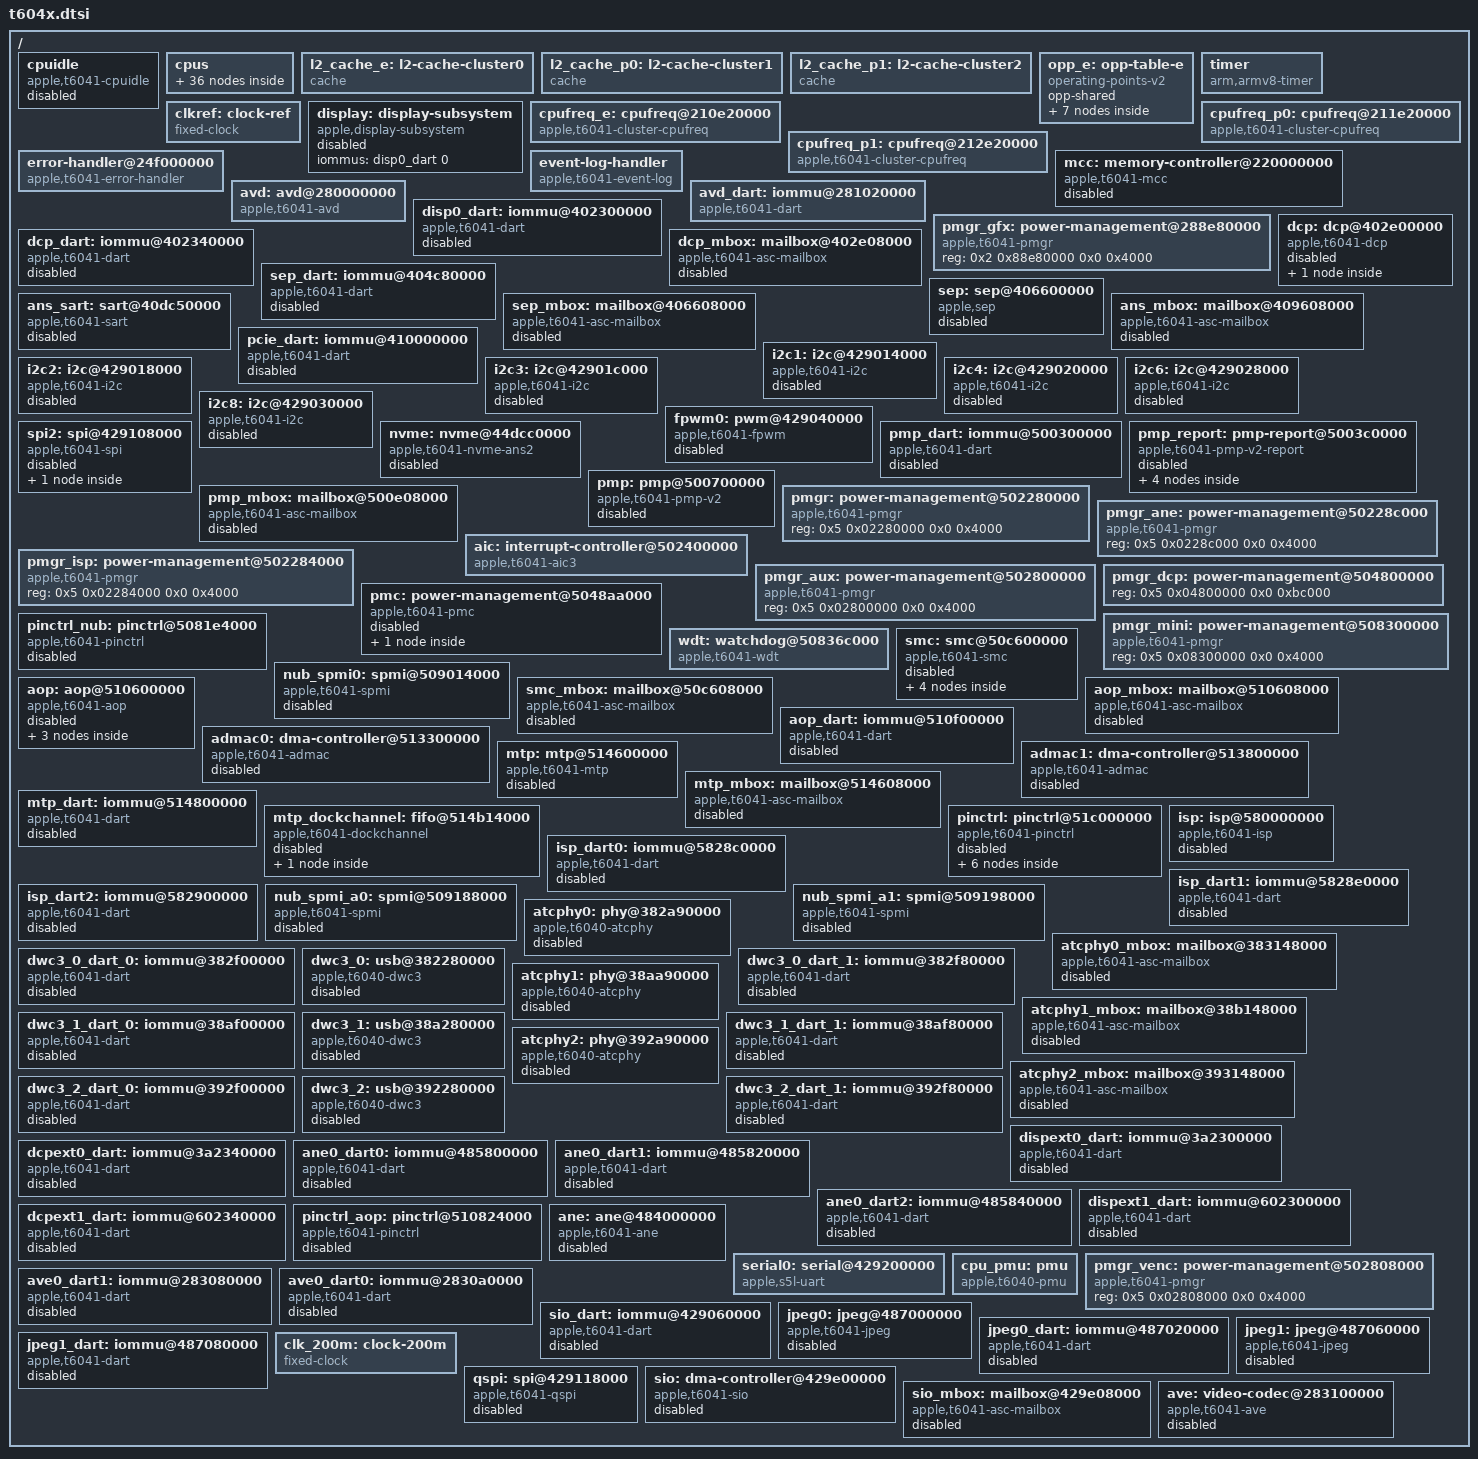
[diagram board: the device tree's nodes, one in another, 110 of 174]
// SPDX-License-Identifier: GPL-2.0+ OR MIT
/*
 * Apple T604x SoC base
 *
 * Unit addresses are the Apple Device Tree's /arm-io addresses plus the
 * 0x2_00000000 arm-io base. The nodes sit at the root, not under a
 * simple-bus: the boot loader edits several of them by path. The blocks
 * known to need non-posted writes carry nonposted-mmio themselves.
 *
 * Copyright The Asahi Linux Contributors
 */

#include <dt-bindings/gpio/gpio.h>
#include <dt-bindings/interrupt-controller/apple-aic.h>
#include <dt-bindings/interrupt-controller/irq.h>
#include <dt-bindings/pinctrl/apple.h>
#include <dt-bindings/phy/phy.h>
#include <dt-bindings/spmi/spmi.h>

/ {
	#address-cells = <2>;
	#size-cells = <2>;

	cpuidle: cpuidle {
		compatible = "apple,t6041-cpuidle";
		status = "disabled";
	};

	cpus {
		#address-cells = <2>;
		#size-cells = <0>;

		/*
		 * The clusters are MPIDR Aff1, which are also the L2 groups.
		 * capacity-dmips-mhz comes from pinned single-core throughput
		 * at the lowest p-state (E 1018 MHz, P 1257 MHz): E/P is 0.652
		 * per MHz, so E 668 and P 1024.
		 */
		cpu-map {
			cluster0 {
				core0 {
					cpu = <&cpu_e0>;
				};
				core1 {
					cpu = <&cpu_e1>;
				};
				core2 {
					cpu = <&cpu_e2>;
				};
				core3 {
					cpu = <&cpu_e3>;
				};
			};

			cluster1 {
				core0 {
					cpu = <&cpu_p00>;
				};
				core1 {
					cpu = <&cpu_p01>;
				};
				core2 {
					cpu = <&cpu_p02>;
				};
				core3 {
					cpu = <&cpu_p03>;
				};
				core4 {
					cpu = <&cpu_p04>;
				};
				core5 {
					cpu = <&cpu_p05>;
				};
			};

			cluster2 {
				core0 {
					cpu = <&cpu_p10>;
				};
				core1 {
					cpu = <&cpu_p11>;
				};
				core2 {
					cpu = <&cpu_p12>;
				};
				core3 {
					cpu = <&cpu_p13>;
				};
				core4 {
					cpu = <&cpu_p14>;
				};
				core5 {
					cpu = <&cpu_p15>;
				};
			};
		};

		/* m1n1 requires CPU nodes in MPIDR order. */
		cpu_e0: cpu@0 {
			compatible = "apple,brava-e";
			device_type = "cpu";
			reg = <0x0 0x0>;
			enable-method = "spin-table";
			cpu-release-addr = <0 0>; /* To be filled by loader */
			next-level-cache = <&l2_cache_e>;
			operating-points-v2 = <&opp_e>;
			capacity-dmips-mhz = <668>;
			performance-domains = <&cpufreq_e>;
			#cooling-cells = <2>;
		};

		cpu_e1: cpu@1 {
			compatible = "apple,brava-e";
			device_type = "cpu";
			reg = <0x0 0x1>;
			enable-method = "spin-table";
			cpu-release-addr = <0 0>; /* To be filled by loader */
			next-level-cache = <&l2_cache_e>;
			operating-points-v2 = <&opp_e>;
			capacity-dmips-mhz = <668>;
			performance-domains = <&cpufreq_e>;
			#cooling-cells = <2>;
		};

		cpu_e2: cpu@2 {
			compatible = "apple,brava-e";
			device_type = "cpu";
			reg = <0x0 0x2>;
			enable-method = "spin-table";
			cpu-release-addr = <0 0>; /* To be filled by loader */
			next-level-cache = <&l2_cache_e>;
			operating-points-v2 = <&opp_e>;
			capacity-dmips-mhz = <668>;
			performance-domains = <&cpufreq_e>;
			#cooling-cells = <2>;
		};

		cpu_e3: cpu@3 {
			compatible = "apple,brava-e";
			device_type = "cpu";
			reg = <0x0 0x3>;
			enable-method = "spin-table";
			cpu-release-addr = <0 0>; /* To be filled by loader */
			next-level-cache = <&l2_cache_e>;
			operating-points-v2 = <&opp_e>;
			capacity-dmips-mhz = <668>;
			performance-domains = <&cpufreq_e>;
			#cooling-cells = <2>;
		};

		/* The boot CPU: the boot loader enters the kernel on it. */
		cpu_p00: cpu@10100 {
			compatible = "apple,brava-p";
			device_type = "cpu";
			reg = <0x0 0x10100>;
			next-level-cache = <&l2_cache_p0>;
			operating-points-v2 = <&opp_p0>;
			capacity-dmips-mhz = <1024>;
			performance-domains = <&cpufreq_p0>;
			#cooling-cells = <2>;
		};

		cpu_p01: cpu@10101 {
			compatible = "apple,brava-p";
			device_type = "cpu";
			reg = <0x0 0x10101>;
			enable-method = "spin-table";
			cpu-release-addr = <0 0>; /* To be filled by loader */
			next-level-cache = <&l2_cache_p0>;
			operating-points-v2 = <&opp_p0>;
			capacity-dmips-mhz = <1024>;
			performance-domains = <&cpufreq_p0>;
			#cooling-cells = <2>;
		};

		cpu_p02: cpu@10102 {
			compatible = "apple,brava-p";
			device_type = "cpu";
			reg = <0x0 0x10102>;
			enable-method = "spin-table";
			cpu-release-addr = <0 0>; /* To be filled by loader */
			next-level-cache = <&l2_cache_p0>;
			operating-points-v2 = <&opp_p0>;
			capacity-dmips-mhz = <1024>;
			performance-domains = <&cpufreq_p0>;
			#cooling-cells = <2>;
		};

		cpu_p03: cpu@10103 {
			compatible = "apple,brava-p";
			device_type = "cpu";
			reg = <0x0 0x10103>;
			enable-method = "spin-table";
			cpu-release-addr = <0 0>; /* To be filled by loader */
			next-level-cache = <&l2_cache_p0>;
			operating-points-v2 = <&opp_p0>;
			capacity-dmips-mhz = <1024>;
			performance-domains = <&cpufreq_p0>;
			#cooling-cells = <2>;
		};

		cpu_p04: cpu@10104 {
			compatible = "apple,brava-p";
			device_type = "cpu";
			reg = <0x0 0x10104>;
			enable-method = "spin-table";
			cpu-release-addr = <0 0>; /* To be filled by loader */
			next-level-cache = <&l2_cache_p0>;
			operating-points-v2 = <&opp_p0>;
			capacity-dmips-mhz = <1024>;
			performance-domains = <&cpufreq_p0>;
			#cooling-cells = <2>;
		};

		cpu_p05: cpu@10105 {
			compatible = "apple,brava-p";
			device_type = "cpu";
			reg = <0x0 0x10105>;
			enable-method = "spin-table";
			cpu-release-addr = <0 0>;
			next-level-cache = <&l2_cache_p0>;
			operating-points-v2 = <&opp_p0>;
			capacity-dmips-mhz = <1024>;
			performance-domains = <&cpufreq_p0>;
			#cooling-cells = <2>;
		};

		cpu_p10: cpu@10200 {
			compatible = "apple,brava-p";
			device_type = "cpu";
			reg = <0x0 0x10200>;
			enable-method = "spin-table";
			cpu-release-addr = <0 0>; /* To be filled by loader */
			next-level-cache = <&l2_cache_p1>;
			operating-points-v2 = <&opp_p1>;
			capacity-dmips-mhz = <1024>;
			performance-domains = <&cpufreq_p1>;
			#cooling-cells = <2>;
		};

		cpu_p11: cpu@10201 {
			compatible = "apple,brava-p";
			device_type = "cpu";
			reg = <0x0 0x10201>;
			enable-method = "spin-table";
			cpu-release-addr = <0 0>; /* To be filled by loader */
			next-level-cache = <&l2_cache_p1>;
			operating-points-v2 = <&opp_p1>;
			capacity-dmips-mhz = <1024>;
			performance-domains = <&cpufreq_p1>;
			#cooling-cells = <2>;
		};

		cpu_p12: cpu@10202 {
			compatible = "apple,brava-p";
			device_type = "cpu";
			reg = <0x0 0x10202>;
			enable-method = "spin-table";
			cpu-release-addr = <0 0>; /* To be filled by loader */
			next-level-cache = <&l2_cache_p1>;
			operating-points-v2 = <&opp_p1>;
			capacity-dmips-mhz = <1024>;
			performance-domains = <&cpufreq_p1>;
			#cooling-cells = <2>;
		};

		cpu_p13: cpu@10203 {
			compatible = "apple,brava-p";
			device_type = "cpu";
			reg = <0x0 0x10203>;
			enable-method = "spin-table";
			cpu-release-addr = <0 0>; /* To be filled by loader */
			next-level-cache = <&l2_cache_p1>;
			operating-points-v2 = <&opp_p1>;
			capacity-dmips-mhz = <1024>;
			performance-domains = <&cpufreq_p1>;
			#cooling-cells = <2>;
		};

		cpu_p14: cpu@10204 {
			compatible = "apple,brava-p";
			device_type = "cpu";
			reg = <0x0 0x10204>;
			enable-method = "spin-table";
			cpu-release-addr = <0 0>; /* To be filled by loader */
			next-level-cache = <&l2_cache_p1>;
			operating-points-v2 = <&opp_p1>;
			capacity-dmips-mhz = <1024>;
			performance-domains = <&cpufreq_p1>;
			#cooling-cells = <2>;
		};

		cpu_p15: cpu@10205 {
			compatible = "apple,brava-p";
			device_type = "cpu";
			reg = <0x0 0x10205>;
			enable-method = "spin-table";
			cpu-release-addr = <0 0>;
			next-level-cache = <&l2_cache_p1>;
			operating-points-v2 = <&opp_p1>;
			capacity-dmips-mhz = <1024>;
			performance-domains = <&cpufreq_p1>;
			#cooling-cells = <2>;
		};
	};

	l2_cache_e: l2-cache-cluster0 {
		compatible = "cache";
		cache-level = <2>;
		cache-unified;
		cache-size = <0x400000>;
	};

	l2_cache_p0: l2-cache-cluster1 {
		compatible = "cache";
		cache-level = <2>;
		cache-unified;
		cache-size = <0x1000000>;
	};

	l2_cache_p1: l2-cache-cluster2 {
		compatible = "cache";
		cache-level = <2>;
		cache-unified;
		cache-size = <0x1000000>;
	};

	/*
	 * DVFS states from the ADT /arm-io/pmgr voltage-states1-sram (E),
	 * voltage-states5-sram (P0) and voltage-states13-sram (P1), word 0 in
	 * kHz; opp-level is the hardware p-state. Each P cluster has its own
	 * table: opp-shared means one clock domain per table.
	 *
	 * opp-microwatt is one busy core's power on a J616s, from the SMC
	 * core-rail meters (P0 PR0b, P1 PP0b, E PP2b). The P values follow a
	 * k * V^2 * f + c fit, as the PMP clips the two top states within
	 * seconds; the E values are the idle cluster plus a quarter of the
	 * four-core increase, since one E core does not register below
	 * 2352 MHz.
	 */
	opp_e: opp-table-e {
		compatible = "operating-points-v2";
		opp-shared;

		opp01 {
			opp-hz = /bits/ 64 <1020000000>;
			opp-level = <1>;
		};
		opp02 {
			opp-hz = /bits/ 64 <1404000000>;
			opp-level = <2>;
		};
		opp03 {
			opp-hz = /bits/ 64 <1788000000>;
			opp-level = <3>;
		};
		opp04 {
			opp-hz = /bits/ 64 <2112000000>;
			opp-level = <4>;
		};
		opp05 {
			opp-hz = /bits/ 64 <2352000000>;
			opp-level = <5>;
		};
		opp06 {
			opp-hz = /bits/ 64 <2532000000>;
			opp-level = <6>;
		};
		opp07 {
			opp-hz = /bits/ 64 <2592000000>;
			opp-level = <7>;
		};
	};

	timer {
		compatible = "arm,armv8-timer";
		interrupt-parent = <&aic>;
		interrupt-names = "phys", "virt", "hyp-phys", "hyp-virt";
		interrupts = <AIC_FIQ AIC_TMR_GUEST_PHYS IRQ_TYPE_LEVEL_HIGH>,
			     <AIC_FIQ AIC_TMR_GUEST_VIRT IRQ_TYPE_LEVEL_HIGH>,
			     <AIC_FIQ AIC_TMR_HV_PHYS IRQ_TYPE_LEVEL_HIGH>,
			     <AIC_FIQ AIC_TMR_HV_VIRT IRQ_TYPE_LEVEL_HIGH>;
	};

	/* The 24 MHz reference clock (ADT clock-ids 4) of the I2C, PWM and watchdog blocks */
	clkref: clock-ref {
		compatible = "fixed-clock";
		#clock-cells = <0>;
		clock-frequency = <24000000>;
		clock-output-names = "clkref";
	};

	/*
	 * Display component master. It has no registers; the boot loader
	 * enables it with the DCP when it hands the display over.
	 */
	display: display-subsystem {
		compatible = "apple,display-subsystem";
		iommus = <&disp0_dart 0>;
		status = "disabled";
	};

	cpufreq_e: cpufreq@210e20000 {
		compatible = "apple,t6041-cluster-cpufreq", "apple,t8112-cluster-cpufreq";
		reg = <0x2 0x10e20000 0x0 0x1000>;
		nonposted-mmio;
		#performance-domain-cells = <0>;
		/* PMP fast die-temperature effort, byte 0 of FAST-DIE-CE */
		apple,fast-die-effort = <&pmp_report 0>;
	};

	cpufreq_p0: cpufreq@211e20000 {
		compatible = "apple,t6041-cluster-cpufreq", "apple,t8112-cluster-cpufreq";
		reg = <0x2 0x11e20000 0x0 0x1000>;
		nonposted-mmio;
		#performance-domain-cells = <0>;
		apple,fast-die-effort = <&pmp_report 1>;
	};

	cpufreq_p1: cpufreq@212e20000 {
		compatible = "apple,t6041-cluster-cpufreq", "apple,t8112-cluster-cpufreq";
		reg = <0x2 0x12e20000 0x0 0x1000>;
		nonposted-mmio;
		#performance-domain-cells = <0>;
		apple,fast-die-effort = <&pmp_report 2>;
	};

	error-handler@24f000000 {
		compatible = "apple,t6041-error-handler", "apple,soc-error-handler";
		reg = <0x2 0x4f000000 0x0 0x00005000>,
		      <0x2 0x50000000 0x0 0x00005000>,
		      <0x2 0x51000000 0x0 0x00005000>,
		      <0x2 0x63100000 0x0 0x00005000>,
		      <0x2 0x64100000 0x0 0x00005000>,
		      <0x2 0x65100000 0x0 0x00005000>,
		      <0x2 0x66100000 0x0 0x00005000>,
		      <0x2 0x63000000 0x0 0x00005000>,
		      <0x2 0x64000000 0x0 0x00005000>,
		      <0x2 0x65000000 0x0 0x00005000>,
		      <0x2 0x66000000 0x0 0x00005000>,
		      <0x2 0x6d000000 0x0 0x00005000>,
		      <0x2 0x6e000000 0x0 0x00005000>,
		      <0x2 0x6f000000 0x0 0x00005000>,
		      <0x2 0x70000000 0x0 0x00005000>,
		      <0x2 0x71000000 0x0 0x00005000>,
		      <0x2 0x72000000 0x0 0x00005000>,
		      <0x2 0x73000000 0x0 0x00005000>,
		      <0x2 0x74000000 0x0 0x00005000>,
		      <0x2 0x5a000000 0x0 0x00005000>,
		      <0x2 0x5b000000 0x0 0x00005000>,
		      <0x2 0x6b000000 0x0 0x00005000>,
		      <0x2 0x6c000000 0x0 0x00005000>,
		      <0x2 0x7b000000 0x0 0x00005000>,
		      <0x2 0x7c000000 0x0 0x00005000>;
		interrupt-parent = <&aic>;
		interrupts = <AIC_IRQ 675 IRQ_TYPE_LEVEL_HIGH>,
			     <AIC_IRQ 684 IRQ_TYPE_LEVEL_HIGH>,
			     <AIC_IRQ 674 IRQ_TYPE_LEVEL_HIGH>,
			     <AIC_IRQ 681 IRQ_TYPE_LEVEL_HIGH>,
			     <AIC_IRQ 679 IRQ_TYPE_LEVEL_HIGH>,
			     <AIC_IRQ 677 IRQ_TYPE_LEVEL_HIGH>,
			     <AIC_IRQ 678 IRQ_TYPE_LEVEL_HIGH>,
			     <AIC_IRQ 682 IRQ_TYPE_LEVEL_HIGH>,
			     <AIC_IRQ 680 IRQ_TYPE_LEVEL_HIGH>,
			     <AIC_IRQ 411 IRQ_TYPE_LEVEL_HIGH>,
			     <AIC_IRQ 487 IRQ_TYPE_LEVEL_HIGH>,
			     <AIC_IRQ 490 IRQ_TYPE_LEVEL_HIGH>,
			     <AIC_IRQ 493 IRQ_TYPE_LEVEL_HIGH>,
			     <AIC_IRQ 496 IRQ_TYPE_LEVEL_HIGH>,
			     <AIC_IRQ 499 IRQ_TYPE_LEVEL_HIGH>,
			     <AIC_IRQ 502 IRQ_TYPE_LEVEL_HIGH>,
			     <AIC_IRQ 505 IRQ_TYPE_LEVEL_HIGH>,
			     <AIC_IRQ 508 IRQ_TYPE_LEVEL_HIGH>,
			     <AIC_IRQ 511 IRQ_TYPE_LEVEL_HIGH>,
			     <AIC_IRQ 514 IRQ_TYPE_LEVEL_HIGH>,
			     <AIC_IRQ 517 IRQ_TYPE_LEVEL_HIGH>,
			     <AIC_IRQ 520 IRQ_TYPE_LEVEL_HIGH>,
			     <AIC_IRQ 523 IRQ_TYPE_LEVEL_HIGH>,
			     <AIC_IRQ 526 IRQ_TYPE_LEVEL_HIGH>,
			     <AIC_IRQ 529 IRQ_TYPE_LEVEL_HIGH>,
			     <AIC_IRQ 532 IRQ_TYPE_LEVEL_HIGH>,
			     <AIC_IRQ 1000 IRQ_TYPE_LEVEL_HIGH>,
			     <AIC_IRQ 386 IRQ_TYPE_LEVEL_HIGH>,
			     <AIC_IRQ 882 IRQ_TYPE_LEVEL_HIGH>,
			     <AIC_IRQ 583 IRQ_TYPE_LEVEL_HIGH>,
			     <AIC_IRQ 584 IRQ_TYPE_LEVEL_HIGH>,
			     <AIC_IRQ 585 IRQ_TYPE_LEVEL_HIGH>,
			     <AIC_IRQ 586 IRQ_TYPE_LEVEL_HIGH>,
			     <AIC_IRQ 589 IRQ_TYPE_LEVEL_HIGH>,
			     <AIC_IRQ 590 IRQ_TYPE_LEVEL_HIGH>,
			     <AIC_IRQ 591 IRQ_TYPE_LEVEL_HIGH>,
			     <AIC_IRQ 592 IRQ_TYPE_LEVEL_HIGH>,
			     <AIC_IRQ 595 IRQ_TYPE_LEVEL_HIGH>,
			     <AIC_IRQ 596 IRQ_TYPE_LEVEL_HIGH>,
			     <AIC_IRQ 597 IRQ_TYPE_LEVEL_HIGH>,
			     <AIC_IRQ 598 IRQ_TYPE_LEVEL_HIGH>,
			     <AIC_IRQ 601 IRQ_TYPE_LEVEL_HIGH>,
			     <AIC_IRQ 602 IRQ_TYPE_LEVEL_HIGH>,
			     <AIC_IRQ 603 IRQ_TYPE_LEVEL_HIGH>,
			     <AIC_IRQ 604 IRQ_TYPE_LEVEL_HIGH>,
			     <AIC_IRQ 175 IRQ_TYPE_LEVEL_HIGH>,
			     <AIC_IRQ 176 IRQ_TYPE_LEVEL_HIGH>,
			     <AIC_IRQ 177 IRQ_TYPE_LEVEL_HIGH>,
			     <AIC_IRQ 182 IRQ_TYPE_LEVEL_HIGH>,
			     <AIC_IRQ 183 IRQ_TYPE_LEVEL_HIGH>,
			     <AIC_IRQ 184 IRQ_TYPE_LEVEL_HIGH>,
			     <AIC_IRQ 185 IRQ_TYPE_LEVEL_HIGH>,
			     <AIC_IRQ 190 IRQ_TYPE_LEVEL_HIGH>,
			     <AIC_IRQ 191 IRQ_TYPE_LEVEL_HIGH>,
			     <AIC_IRQ 192 IRQ_TYPE_LEVEL_HIGH>,
			     <AIC_IRQ 193 IRQ_TYPE_LEVEL_HIGH>,
			     <AIC_IRQ 256 IRQ_TYPE_LEVEL_HIGH>,
			     <AIC_IRQ 257 IRQ_TYPE_LEVEL_HIGH>,
			     <AIC_IRQ 258 IRQ_TYPE_LEVEL_HIGH>,
			     <AIC_IRQ 259 IRQ_TYPE_LEVEL_HIGH>,
			     <AIC_IRQ 260 IRQ_TYPE_LEVEL_HIGH>,
			     <AIC_IRQ 261 IRQ_TYPE_LEVEL_HIGH>,
			     <AIC_IRQ 262 IRQ_TYPE_LEVEL_HIGH>,
			     <AIC_IRQ 263 IRQ_TYPE_LEVEL_HIGH>,
			     <AIC_IRQ 178 IRQ_TYPE_LEVEL_HIGH>,
			     <AIC_IRQ 179 IRQ_TYPE_LEVEL_HIGH>,
			     <AIC_IRQ 180 IRQ_TYPE_LEVEL_HIGH>,
			     <AIC_IRQ 181 IRQ_TYPE_LEVEL_HIGH>,
			     <AIC_IRQ 254 IRQ_TYPE_LEVEL_HIGH>,
			     <AIC_IRQ 255 IRQ_TYPE_LEVEL_HIGH>,
			     <AIC_IRQ 214 IRQ_TYPE_LEVEL_HIGH>,
			     <AIC_IRQ 215 IRQ_TYPE_LEVEL_HIGH>,
			     <AIC_IRQ 216 IRQ_TYPE_LEVEL_HIGH>,
			     <AIC_IRQ 217 IRQ_TYPE_LEVEL_HIGH>,
			     <AIC_IRQ 222 IRQ_TYPE_LEVEL_HIGH>,
			     <AIC_IRQ 223 IRQ_TYPE_LEVEL_HIGH>,
			     <AIC_IRQ 224 IRQ_TYPE_LEVEL_HIGH>,
			     <AIC_IRQ 225 IRQ_TYPE_LEVEL_HIGH>,
			     <AIC_IRQ 226 IRQ_TYPE_LEVEL_HIGH>,
			     <AIC_IRQ 227 IRQ_TYPE_LEVEL_HIGH>,
			     <AIC_IRQ 228 IRQ_TYPE_LEVEL_HIGH>,
			     <AIC_IRQ 233 IRQ_TYPE_LEVEL_HIGH>,
			     <AIC_IRQ 234 IRQ_TYPE_LEVEL_HIGH>,
			     <AIC_IRQ 235 IRQ_TYPE_LEVEL_HIGH>,
			     <AIC_IRQ 236 IRQ_TYPE_LEVEL_HIGH>,
			     <AIC_IRQ 237 IRQ_TYPE_LEVEL_HIGH>,
			     <AIC_IRQ 238 IRQ_TYPE_LEVEL_HIGH>,
			     <AIC_IRQ 239 IRQ_TYPE_LEVEL_HIGH>,
			     <AIC_IRQ 240 IRQ_TYPE_LEVEL_HIGH>;
	};

	event-log-handler {
		compatible = "apple,t6041-event-log", "apple,soc-event-log";
		interrupt-parent = <&aic>;
		interrupts = <AIC_IRQ 25 IRQ_TYPE_LEVEL_HIGH>,
			     <AIC_IRQ 26 IRQ_TYPE_LEVEL_HIGH>,
			     <AIC_IRQ 27 IRQ_TYPE_LEVEL_HIGH>,
			     <AIC_IRQ 37 IRQ_TYPE_LEVEL_HIGH>,
			     <AIC_IRQ 387 IRQ_TYPE_LEVEL_HIGH>,
			     <AIC_IRQ 401 IRQ_TYPE_LEVEL_HIGH>,
			     <AIC_IRQ 471 IRQ_TYPE_LEVEL_HIGH>,
			     <AIC_IRQ 474 IRQ_TYPE_LEVEL_HIGH>,
			     <AIC_IRQ 475 IRQ_TYPE_LEVEL_HIGH>,
			     <AIC_IRQ 476 IRQ_TYPE_LEVEL_HIGH>,
			     <AIC_IRQ 352 IRQ_TYPE_LEVEL_HIGH>,
			     <AIC_IRQ 346 IRQ_TYPE_LEVEL_HIGH>,
			     <AIC_IRQ 347 IRQ_TYPE_LEVEL_HIGH>,
			     <AIC_IRQ 883 IRQ_TYPE_LEVEL_HIGH>,
			     <AIC_IRQ 1041 IRQ_TYPE_LEVEL_HIGH>,
			     <AIC_IRQ 1049 IRQ_TYPE_LEVEL_HIGH>,
			     <AIC_IRQ 1509 IRQ_TYPE_LEVEL_HIGH>,
			     <AIC_IRQ 1511 IRQ_TYPE_LEVEL_HIGH>,
			     <AIC_IRQ 1517 IRQ_TYPE_LEVEL_HIGH>,
			     <AIC_IRQ 1520 IRQ_TYPE_LEVEL_HIGH>,
			     <AIC_IRQ 1524 IRQ_TYPE_LEVEL_HIGH>;
	};

	/*
	 * System level cache planes: four AMCCs with four planes each.
	 * Allocation waits for the display, which takes over the scan-out DMA
	 * the boot loader left running.
	 */
	mcc: memory-controller@220000000 {
		compatible = "apple,t6041-mcc", "apple,t8140-mcc";
		reg = <0x2 0x20000000 0x0 0x4000>,
		      <0x2 0x20040000 0x0 0x4000>,
		      <0x2 0x20080000 0x0 0x4000>,
		      <0x2 0x200c0000 0x0 0x4000>,
		      <0x2 0x22000000 0x0 0x4000>,
		      <0x2 0x22040000 0x0 0x4000>,
		      <0x2 0x22080000 0x0 0x4000>,
		      <0x2 0x220c0000 0x0 0x4000>,
		      <0x2 0x24000000 0x0 0x4000>,
		      <0x2 0x24040000 0x0 0x4000>,
		      <0x2 0x24080000 0x0 0x4000>,
		      <0x2 0x240c0000 0x0 0x4000>,
		      <0x2 0x26000000 0x0 0x4000>,
		      <0x2 0x26040000 0x0 0x4000>,
		      <0x2 0x26080000 0x0 0x4000>,
		      <0x2 0x260c0000 0x0 0x4000>;
		nonposted-mmio;
		apple,boot-dma-devices = <&display>;
		status = "disabled";
	};

	/*
	 * The decoder firmware programs the T8122/T8132 register family, so
	 * the driver binds through its T8132 entry. The ADT gives the whole
	 * block (0x2_80000000, 0x1404000); the windows follow the T6030/T8140
	 * layout, with the CM3 SRAM between its code and the mailbox.
	 */
	avd: avd@280000000 {
		compatible = "apple,t6041-avd", "apple,t8132-avd";
		reg = <0x2 0x81080000 0x0 0x14000>,
		      <0x2 0x81094000 0x0 0x14000>,
		      <0x2 0x810a8000 0x0 0x4000>,
		      <0x2 0x81100000 0x0 0x10000>;
		reg-names = "code", "sram", "mbox", "ctrl";
		interrupt-parent = <&aic>;
		interrupts = <AIC_IRQ 1442 IRQ_TYPE_LEVEL_HIGH>,
			     <AIC_IRQ 1443 IRQ_TYPE_LEVEL_HIGH>;
		resets = <&ps_avd_sys>;
		iommus = <&avd_dart 0>;
		dma-coherent;
	};

	avd_dart: iommu@281020000 {
		compatible = "apple,t6041-dart", "apple,t8110-dart";
		reg = <0x2 0x81020000 0x0 0xc000>;
		#iommu-cells = <1>;
		interrupt-parent = <&aic>;
		interrupts = <AIC_IRQ 1449 IRQ_TYPE_LEVEL_HIGH>;
		power-domains = <&ps_avd_sys>;
	};

	pmgr_gfx: power-management@288e80000 {
		compatible = "apple,t6041-pmgr", "apple,t8103-pmgr", "syscon", "simple-mfd";
		#address-cells = <1>;
		#size-cells = <1>;
		reg = <0x2 0x88e80000 0x0 0x4000>;
		/* child nodes are added in t604x-pmgr.dtsi */
	};

	disp0_dart: iommu@402300000 {
		compatible = "apple,t6041-dart", "apple,t8110-dart";
		reg = <0x4 0x02300000 0x0 0xc000>;
		#iommu-cells = <1>;
		apple,dma-range = <0x100 0x0 0x10 0x0>;
		interrupt-parent = <&aic>;
		interrupts = <AIC_IRQ 1090 IRQ_TYPE_LEVEL_HIGH>;
		status = "disabled";
	};

	dcp_dart: iommu@402340000 {
		compatible = "apple,t6041-dart", "apple,t8110-dart";
		reg = <0x4 0x02340000 0x0 0x20000>;
		#iommu-cells = <1>;
		apple,dma-range = <0x100 0x0 0x10 0x0>;
		interrupt-parent = <&aic>;
		interrupts = <AIC_IRQ 1090 IRQ_TYPE_LEVEL_HIGH>;
		status = "disabled";
	};

	dcp: dcp@402e00000 {
		compatible = "apple,t6041-dcp", "apple,dcp";
		reg = <0x4 0x02e00000 0x0 0x4000>,
		      <0x4 0x00000000 0x0 0x4000000>,
		      <0x4 0x02240000 0x0 0x10000>,
		      <0x4 0x023a8000 0x0 0x4000>,
		      <0x4 0x02800000 0x0 0x800000>;
		reg-names = "coproc", "disp-0", "disp-1", "disp-2", "disp-3";
		mboxes = <&dcp_mbox>;
		mbox-names = "mbox";
		iommus = <&dcp_dart 23>;
		apple,bw-scratch = <&pmgr_dcp 0 4 0x20000>;
		apple,iomfb-surfaces = <1 1 0 0>;
		/* the boot loader describes the piodma's regions with 2+2 cells */
		#address-cells = <2>;
		#size-cells = <2>;
		/* enabled once the boot loader has handed the display over */
		status = "disabled";

		disp0_piodma: piodma {
			iommus = <&disp0_dart 16>;
		};
	};

	dcp_mbox: mailbox@402e08000 {
		compatible = "apple,t6041-asc-mailbox", "apple,asc-mailbox-v4";
		reg = <0x4 0x02e08000 0x0 0x4000>;
		interrupt-parent = <&aic>;
		interrupts = <AIC_IRQ 1143 IRQ_TYPE_LEVEL_HIGH>,
			     <AIC_IRQ 1144 IRQ_TYPE_LEVEL_HIGH>,
			     <AIC_IRQ 1145 IRQ_TYPE_LEVEL_HIGH>,
			     <AIC_IRQ 1146 IRQ_TYPE_LEVEL_HIGH>;
		interrupt-names = "send-empty", "send-not-empty",
				  "recv-empty", "recv-not-empty";
		#mbox-cells = <0>;
		status = "disabled";
	};

	/*
	 * iBoot hands over a running SEP. Keep Linux off its DART at boot;
	 * apple_sep enables it when the driver binds. The SEP only accepts
	 * IOVAs in the window iBoot programmed (ADT vm-base 0x10000004000,
	 * vm-size 0x3ff00000), which carries the BIT(40) alias the DART
	 * translates.
	 */
	sep_dart: iommu@404c80000 {
		compatible = "apple,t6041-dart", "apple,t8110-dart";
		reg = <0x4 0x04c80000 0x0 0x20000>;
		interrupt-parent = <&aic>;
		interrupts = <AIC_IRQ 676 IRQ_TYPE_LEVEL_HIGH>;
		#iommu-cells = <1>;
		apple,dma-range = /bits/ 64 <0x10000004000 0x3ff00000>;
		apple,dma-offset = /bits/ 64 <0x0>;
		status = "disabled";
	};

	sep: sep@406600000 {
		compatible = "apple,sep";
		reg = <0x4 0x06600000 0x0 0x88000>;
		mboxes = <&sep_mbox>;
		mbox-names = "mbox";
		iommus = <&sep_dart 0>;
		power-domains = <&ps_sep>;
		status = "disabled";
	};

	sep_mbox: mailbox@406608000 {
		compatible = "apple,t6041-asc-mailbox", "apple,asc-mailbox-v4";
		reg = <0x4 0x06608000 0x0 0x4000>;
		interrupt-parent = <&aic>;
		interrupts = <AIC_IRQ 666 IRQ_TYPE_LEVEL_HIGH>,
			     <AIC_IRQ 667 IRQ_TYPE_LEVEL_HIGH>,
			     <AIC_IRQ 668 IRQ_TYPE_LEVEL_HIGH>,
			     <AIC_IRQ 669 IRQ_TYPE_LEVEL_HIGH>;
		interrupt-names = "send-empty", "send-not-empty",
				  "recv-empty", "recv-not-empty";
		#mbox-cells = <0>;
		status = "disabled";
	};

	ans_mbox: mailbox@409608000 {
		compatible = "apple,t6041-asc-mailbox", "apple,asc-mailbox-v4";
		reg = <0x4 0x09608000 0x0 0x4000>;
		interrupt-parent = <&aic>;
		interrupts = <AIC_IRQ 1530 IRQ_TYPE_LEVEL_HIGH>,
			     <AIC_IRQ 1531 IRQ_TYPE_LEVEL_HIGH>,
			     <AIC_IRQ 1532 IRQ_TYPE_LEVEL_HIGH>,
			     <AIC_IRQ 1533 IRQ_TYPE_LEVEL_HIGH>;
		interrupt-names = "send-empty", "send-not-empty",
				  "recv-empty", "recv-not-empty";
		power-domains = <&ps_ans>;
		#mbox-cells = <0>;
		status = "disabled";
	};

	ans_sart: sart@40dc50000 {
		compatible = "apple,t6041-sart", "apple,t6000-sart";
		reg = <0x4 0x0dc50000 0x0 0xc000>;
		power-domains = <&ps_ans>;
		status = "disabled";
	};

	pcie_dart: iommu@410000000 {
		compatible = "apple,t6041-dart", "apple,t8110-dart";
		reg = <0x4 0x10000000 0x0 0x20000>;
		#iommu-cells = <1>;
		interrupt-parent = <&aic>;
		interrupts = <AIC_IRQ 1724 IRQ_TYPE_LEVEL_HIGH>;
		status = "disabled";
	};

	/* iBoot leaves the I2C gates on and the pins muxed to I2C. */
	i2c1: i2c@429014000 {
		compatible = "apple,t6041-i2c", "apple,t8103-i2c";
		reg = <0x4 0x29014000 0x0 0x4000>;
		clocks = <&clkref>;
		interrupt-parent = <&aic>;
		interrupts = <AIC_IRQ 1576 IRQ_TYPE_LEVEL_HIGH>;
		pinctrl-0 = <&i2c1_pins>;
		pinctrl-names = "default";
		power-domains = <&ps_i2c1>;
		#address-cells = <1>;
		#size-cells = <0>;
		status = "disabled";
	};

	i2c2: i2c@429018000 {
		compatible = "apple,t6041-i2c", "apple,t8103-i2c";
		reg = <0x4 0x29018000 0x0 0x4000>;
		clocks = <&clkref>;
		interrupt-parent = <&aic>;
		interrupts = <AIC_IRQ 1577 IRQ_TYPE_LEVEL_HIGH>;
		pinctrl-0 = <&i2c2_pins>;
		pinctrl-names = "default";
		power-domains = <&ps_i2c2>;
		#address-cells = <1>;
		#size-cells = <0>;
		status = "disabled";
	};

	i2c3: i2c@42901c000 {
		compatible = "apple,t6041-i2c", "apple,t8103-i2c";
		reg = <0x4 0x2901c000 0x0 0x4000>;
		clocks = <&clkref>;
		interrupt-parent = <&aic>;
		interrupts = <AIC_IRQ 1578 IRQ_TYPE_LEVEL_HIGH>;
		pinctrl-0 = <&i2c3_pins>;
		pinctrl-names = "default";
		power-domains = <&ps_i2c3>;
		#address-cells = <1>;
		#size-cells = <0>;
		status = "disabled";
	};

	i2c4: i2c@429020000 {
		compatible = "apple,t6041-i2c", "apple,t8103-i2c";
		reg = <0x4 0x29020000 0x0 0x4000>;
		clocks = <&clkref>;
		interrupt-parent = <&aic>;
		interrupts = <AIC_IRQ 1579 IRQ_TYPE_LEVEL_HIGH>;
		pinctrl-0 = <&i2c4_pins>;
		pinctrl-names = "default";
		power-domains = <&ps_i2c4>;
		#address-cells = <1>;
		#size-cells = <0>;
		status = "disabled";
	};

	i2c6: i2c@429028000 {
		compatible = "apple,t6041-i2c", "apple,t8103-i2c";
		reg = <0x4 0x29028000 0x0 0x4000>;
		clocks = <&clkref>;
		interrupt-parent = <&aic>;
		interrupts = <AIC_IRQ 1581 IRQ_TYPE_LEVEL_HIGH>;
		pinctrl-0 = <&i2c6_pins>;
		pinctrl-names = "default";
		power-domains = <&ps_i2c6>;
		#address-cells = <1>;
		#size-cells = <0>;
		status = "disabled";
	};

	i2c8: i2c@429030000 {
		compatible = "apple,t6041-i2c", "apple,t8103-i2c";
		reg = <0x4 0x29030000 0x0 0x4000>;
		clocks = <&clkref>;
		interrupt-parent = <&aic>;
		interrupts = <AIC_IRQ 1583 IRQ_TYPE_LEVEL_HIGH>;
		pinctrl-0 = <&i2c8_pins>;
		pinctrl-names = "default";
		power-domains = <&ps_i2c8>;
		#address-cells = <1>;
		#size-cells = <0>;
		status = "disabled";
	};

	fpwm0: pwm@429040000 {
		compatible = "apple,t6041-fpwm", "apple,s5l-fpwm";
		reg = <0x4 0x29040000 0x0 0x4000>;
		clocks = <&clkref>;
		power-domains = <&ps_fpwm0>;
		#pwm-cells = <2>;
		status = "disabled";
	};

	/*
	 * Touch ID. iBoot leaves the pads muxed and the controller uses its
	 * native chip select, so there is no pinctrl here.
	 */
	spi2: spi@429108000 {
		compatible = "apple,t6041-spi", "apple,t8103-spi";
		reg = <0x4 0x29108000 0x0 0x4000>;
		interrupt-parent = <&aic>;
		interrupts = <AIC_IRQ 1569 IRQ_TYPE_LEVEL_HIGH>;
		clocks = <&clkref>;
		power-domains = <&ps_spi2>;
		#address-cells = <1>;
		#size-cells = <0>;
		status = "disabled";

		mesa: fingerprint@0 {
			compatible = "apple,mesa-fingerprint";
			reg = <0>;
			spi-max-frequency = <8000000>;
			spi-cpol;
			status = "disabled";
		};
	};

	nvme: nvme@44dcc0000 {
		compatible = "apple,t6041-nvme-ans2";
		reg = <0x4 0x4dcc0000 0x0 0x10000>,
		      <0x4 0x09600000 0x0 0x4000>,
		      <0x4 0x0dcc0000 0x0 0x60000>;
		reg-names = "nvme", "ans", "nvmmu";
		interrupt-parent = <&aic>;
		interrupts = <AIC_IRQ 2583 IRQ_TYPE_LEVEL_HIGH>;
		mboxes = <&ans_mbox>;
		apple,sart = <&ans_sart>;
		power-domains = <&ps_ans>, <&ps_apcie_sys_st0>,
				<&ps_apcie_sys_st1>;
		power-domain-names = "ans", "apcie0", "apcie1";
		resets = <&ps_ans>;
		status = "disabled";
	};

	/*
	 * PMP (power management coprocessor). iBoot locks its DART (PROTECT
	 * 0x1e7, SIDs 0 and 1 translating): apple-dart adopts iBoot's SID 0
	 * table and leaves SID 1 alone. apple,dma-range keeps Linux's IOVAs
	 * in the ADT window (vm-base 0x100_0000_0000, 64 GiB). The DART's
	 * second ADT range is the SoC's shared clock-protection block, not
	 * part of the DART.
	 */
	pmp_dart: iommu@500300000 {
		compatible = "apple,t6041-dart", "apple,t8110-dart";
		reg = <0x5 0x00300000 0x0 0xc000>;
		interrupt-parent = <&aic>;
		interrupts = <AIC_IRQ 389 IRQ_TYPE_LEVEL_HIGH>;
		#iommu-cells = <1>;
		apple,dma-range = <0x100 0x0 0x10 0x0>;
		power-domains = <&ps_pmp>;
		status = "disabled";
	};

	/*
	 * Report (PTD) region: reads 16 bytes per entry at +0x0, writes 8
	 * bytes per entry at +0x10000. Entries are PMP soc-devices; every
	 * entry reads 0 while the PMP is stopped.
	 */
	pmp_report: pmp-report@5003c0000 {
		compatible = "apple,t6041-pmp-v2-report";
		reg = <0x5 0x003c0000 0x0 0x20000>;
		nonposted-mmio;
		power-domains = <&ps_pms_sram>;
		#address-cells = <1>;
		#size-cells = <0>;
		status = "disabled";

		/* The CPU clusters, for their fast die-temperature loops */
		report@a {
			compatible = "apple,t6041-pmp-v2-report-entry",
				     "apple,t6000-pmp-v2-report-entry";
			reg = <0xa>;
			label = "pmp-eacc0";
			#power-domain-cells = <0>;
			apple,always-on;
		};

		report@b {
			compatible = "apple,t6041-pmp-v2-report-entry",
				     "apple,t6000-pmp-v2-report-entry";
			reg = <0xb>;
			label = "pmp-pacc0";
			#power-domain-cells = <0>;
			apple,always-on;
		};

		report@c {
			compatible = "apple,t6041-pmp-v2-report-entry",
				     "apple,t6000-pmp-v2-report-entry";
			reg = <0xc>;
			label = "pmp-pacc1";
			#power-domain-cells = <0>;
			apple,always-on;
		};

		/*
		 * The GPU (soc-device 13). Without it the running PMP treats
		 * the GPU as off and holds it at its lowest state, but claiming
		 * it while nothing powers the GPU crashes the PMP firmware
		 * (SError) right after it starts. It sits on the GPU's own
		 * power state. The GPU consumer takes this domain, so the request
		 * follows the GFX domain's power lifetime.
		 */
		pmp_gfx: report@d {
			compatible = "apple,t6041-pmp-v2-report-entry",
				     "apple,t6000-pmp-v2-report-entry";
			reg = <0xd>;
			label = "pmp-gfx";
			#power-domain-cells = <0>;
			power-domains = <&ps_gfx>;
		};
	};

	/*
	 * The boot loader adds the per-unit properties (board, DRAM) and the
	 * firmware tunables the driver needs before it starts the PMP.
	 */
	pmp: pmp@500700000 {
		compatible = "apple,t6041-pmp-v2", "apple,t6000-pmp-v2";
		reg = <0x5 0x00700000 0x0 0xe0000>,
		      <0x5 0x00e00000 0x0 0x4000>;
		reg-names = "pmp", "asc";
		mboxes = <&pmp_mbox>;
		mbox-names = "mbox";
		iommus = <&pmp_dart 0>;
		power-domains = <&ps_pmp>;
		apple,pmc = <1>;
		apple,pmc-pmgr = <0x3f>;
		status = "disabled";
	};

	pmp_mbox: mailbox@500e08000 {
		compatible = "apple,t6041-asc-mailbox", "apple,asc-mailbox-v4";
		reg = <0x5 0x00e08000 0x0 0x4000>;
		interrupt-parent = <&aic>;
		interrupts = <AIC_IRQ 414 IRQ_TYPE_LEVEL_HIGH>,
			     <AIC_IRQ 415 IRQ_TYPE_LEVEL_HIGH>,
			     <AIC_IRQ 416 IRQ_TYPE_LEVEL_HIGH>,
			     <AIC_IRQ 417 IRQ_TYPE_LEVEL_HIGH>;
		interrupt-names = "send-empty", "send-not-empty",
				  "recv-empty", "recv-not-empty";
		power-domains = <&ps_pmp>, <&ps_pms_sram>;
		#mbox-cells = <0>;
		status = "disabled";
	};

	pmgr: power-management@502280000 {
		compatible = "apple,t6041-pmgr", "apple,t8103-pmgr", "syscon", "simple-mfd";
		#address-cells = <1>;
		#size-cells = <1>;
		reg = <0x5 0x02280000 0x0 0x4000>;
		/* child nodes are added in t604x-pmgr.dtsi */
	};

	pmgr_ane: power-management@50228c000 {
		compatible = "apple,t6041-pmgr", "apple,t8103-pmgr", "syscon", "simple-mfd";
		reg = <0x5 0x0228c000 0x0 0x4000>;
		#address-cells = <1>;
		#size-cells = <1>;
	};

	pmgr_isp: power-management@502284000 {
		compatible = "apple,t6041-pmgr", "apple,t8103-pmgr", "syscon", "simple-mfd";
		#address-cells = <1>;
		#size-cells = <1>;
		reg = <0x5 0x02284000 0x0 0x4000>;
		/* child nodes are added in t604x-pmgr.dtsi */
	};

	aic: interrupt-controller@502400000 {
		compatible = "apple,t6041-aic3", "apple,t8122-aic3";
		#interrupt-cells = <3>;
		interrupt-controller;
		reg = <0x5 0x02400000 0x0 0x184000>,
		      <0x5 0x02440000 0x0 0x4>;
		reg-names = "core", "event";
	};

	pmgr_aux: power-management@502800000 {
		compatible = "apple,t6041-pmgr", "apple,t8103-pmgr", "syscon", "simple-mfd";
		#address-cells = <1>;
		#size-cells = <1>;
		reg = <0x5 0x02800000 0x0 0x4000>;
		/* child nodes are added in t604x-pmgr.dtsi */
	};

	/*
	 * The PMGR range the DCP driver hands to its firmware; apple,bw-scratch
	 * points into it.
	 */
	pmgr_dcp: power-management@504800000 {
		reg = <0x5 0x04800000 0x0 0xbc000>;
		reg-names = "dcp-fw-pmgr";
		#apple,bw-scratch-cells = <3>;
	};

	/*
	 * PMC voter interface: agent a's floor word at "voters" + 0x4000 * a,
	 * and the rail enables at "rails". Both lie inside pmgr_dcp's range,
	 * which the DCP driver only hands to its firmware; "rails" comes first
	 * so this node's unit address differs from pmgr_dcp's.
	 *
	 * Static voters are the PMP (0), CLPC (1) and AP (3). The PMP votes
	 * the DCS and fabric for non-CPU memory clients such as the GPU, and
	 * iBoot leaves its floor at the top DCS state, so apple,pmp keeps the
	 * PMC off until the PMP driver has bound.
	 */
	pmc: power-management@5048aa000 {
		compatible = "apple,t6041-pmc";
		reg = <0x5 0x048aa000 0x0 0x3000>,
		      <0x5 0x04800000 0x0 0x10000>;
		reg-names = "rails", "voters";
		nonposted-mmio;
		#address-cells = <1>;
		#size-cells = <0>;
		apple,static-voters = <0 1 3>;
		status = "disabled";

		clpc: performance-controller@1 {
			compatible = "apple,t6041-clpc";
			reg = <1>;
			/* High Power mode goes to the SMC on boards with apple,high-power-mode */
			apple,smc = <&smc>;
		};
	};

	/*
	 * The always-on GPIO bank (ADT /arm-io/nub-gpio0, 61 pins). Its power
	 * state is in the always-on PMGR.
	 */
	pinctrl_nub: pinctrl@5081e4000 {
		compatible = "apple,t6041-pinctrl", "apple,t8103-pinctrl";
		reg = <0x5 0x081e4000 0x0 0x4000>;
		power-domains = <&ps_nub_gpio>;

		gpio-controller;
		#gpio-cells = <2>;
		gpio-ranges = <&pinctrl_nub 0 0 61>;
		apple,npins = <61>;

		interrupt-controller;
		#interrupt-cells = <2>;
		interrupt-parent = <&aic>;
		interrupts = <AIC_IRQ 819 IRQ_TYPE_LEVEL_HIGH>,
			     <AIC_IRQ 820 IRQ_TYPE_LEVEL_HIGH>,
			     <AIC_IRQ 821 IRQ_TYPE_LEVEL_HIGH>,
			     <AIC_IRQ 822 IRQ_TYPE_LEVEL_HIGH>,
			     <AIC_IRQ 823 IRQ_TYPE_LEVEL_HIGH>,
			     <AIC_IRQ 824 IRQ_TYPE_LEVEL_HIGH>,
			     <AIC_IRQ 825 IRQ_TYPE_LEVEL_HIGH>;
		status = "disabled";
	};

	pmgr_mini: power-management@508300000 {
		compatible = "apple,t6041-pmgr", "apple,t8103-pmgr", "syscon", "simple-mfd";
		#address-cells = <1>;
		#size-cells = <1>;
		reg = <0x5 0x08300000 0x0 0x4000>;
		/* child nodes are added in t604x-pmgr.dtsi */
	};

	/*
	 * The driver arms the reset only when userspace opens /dev/watchdog
	 * or the firmware left it running; it also provides restart.
	 */
	wdt: watchdog@50836c000 {
		compatible = "apple,t6041-wdt", "apple,t8103-wdt";
		reg = <0x5 0x0836c000 0x0 0x4000>;
		clocks = <&clkref>;
		interrupt-parent = <&aic>;
		interrupts = <AIC_IRQ 827 IRQ_TYPE_LEVEL_HIGH>;
	};

	nub_spmi0: spmi@509014000 {
		compatible = "apple,t6041-spmi", "apple,t8103-spmi";
		reg = <0x5 0x09014000 0x0 0x100>;
		#address-cells = <2>;
		#size-cells = <0>;
		#interrupt-cells = <2>;
		interrupt-controller;
		interrupt-parent = <&aic>;
		interrupts = <AIC_IRQ 0x340 IRQ_TYPE_LEVEL_HIGH>;
		status = "disabled";
	};

	smc: smc@50c600000 {
		compatible = "apple,t6041-smc", "apple,t8103-smc";
		reg = <0x5 0x0c600000 0x0 0x4000>,
		      <0x5 0x0de70000 0x0 0x100000>;
		reg-names = "smc", "sram";
		mboxes = <&smc_mbox>;
		status = "disabled";

		smc_gpio: gpio {
			compatible = "apple,smc-gpio";
			gpio-controller;
			#gpio-cells = <2>;
		};

		smc_hwmon: hwmon {
			compatible = "apple,smc-hwmon";
			#thermal-sensor-cells = <1>;
		};

		smc_reboot: reboot {
			compatible = "apple,smc-reboot";
			nvmem-cells = <&shutdown_flag>, <&boot_stage>,
				      <&boot_error_count>, <&panic_count>;
			nvmem-cell-names = "shutdown_flag", "boot_stage",
					   "boot_error_count", "panic_count";
		};

		smc_rtc: rtc {
			compatible = "apple,smc-rtc";
			nvmem-cells = <&rtc_offset>;
			nvmem-cell-names = "rtc_offset";
		};
	};

	smc_mbox: mailbox@50c608000 {
		compatible = "apple,t6041-asc-mailbox", "apple,asc-mailbox-v4";
		reg = <0x5 0x0c608000 0x0 0x4000>;
		interrupt-parent = <&aic>;
		interrupts = <AIC_IRQ 996 IRQ_TYPE_LEVEL_HIGH>,
			     <AIC_IRQ 997 IRQ_TYPE_LEVEL_HIGH>,
			     <AIC_IRQ 998 IRQ_TYPE_LEVEL_HIGH>,
			     <AIC_IRQ 999 IRQ_TYPE_LEVEL_HIGH>;
		interrupt-names = "send-empty", "send-not-empty",
				  "recv-empty", "recv-not-empty";
		#mbox-cells = <0>;
		status = "disabled";
	};

	/*
	 * AOP (always-on processor). The boot loader loads its RTKit firmware
	 * and leaves it stopped; Linux starts it.
	 */
	aop: aop@510600000 {
		compatible = "apple,t6041-aop";
		reg = <0x5 0x10c10000 0x0 0x2e0000>,
		      <0x5 0x10600000 0x0 0x88000>,
		      <0x5 0x10050000 0x0 0x4000>,
		      <0x5 0x08328000 0x0 0x24>;
		reg-names = "firmware", "asc", "asc-aux", "config";
		mboxes = <&aop_mbox>;
		mbox-names = "mbox";
		iommus = <&aop_dart 0>;
		status = "disabled";

		/*
		 * "dma" is the microphones' LEAP ADMAC channel; "spkr" and
		 * "sense" are the speaker stream's base-ns ADMAC channels 0 and
		 * 1 (ADT audio-speaker dma-channels), "cout" and "cin" the
		 * headphone jack's channels 4 and 5 (TX2 and RX2, ADT
		 * audio-codec-output and audio-codec-input).
		 */
		aop_audio: audio {
			compatible = "apple,t6041-aop-audio", "apple,t6030-aop-audio";
			dmas = <&admac0 1>, <&admac1 0>, <&admac1 1>, <&admac1 4>,
			       <&admac1 5>;
			dma-names = "dma", "spkr", "sense", "cout", "cin";
			/*
			 * The low-power microphone ring: the stream of the ADT
			 * I/O buffer device, shared with admac-base-ns.
			 */
			iommus = <&aop_dart 8>;
			#sound-dai-cells = <1>;
		};

		aop_als: als {
			compatible = "apple,t6041-aop-als", "apple,aop-als";
		};

		aop_las: las {
			compatible = "apple,t6041-aop-las", "apple,aop-las";
		};
	};

	/* ADT lists the interrupts as 1, 0, 3, 2 of the block: send-empty is the lowest. */
	aop_mbox: mailbox@510608000 {
		compatible = "apple,t6041-asc-mailbox", "apple,asc-mailbox-v4";
		reg = <0x5 0x10608000 0x0 0x4000>;
		interrupt-parent = <&aic>;
		interrupts = <AIC_IRQ 710 IRQ_TYPE_LEVEL_HIGH>,
			     <AIC_IRQ 711 IRQ_TYPE_LEVEL_HIGH>,
			     <AIC_IRQ 712 IRQ_TYPE_LEVEL_HIGH>,
			     <AIC_IRQ 713 IRQ_TYPE_LEVEL_HIGH>;
		interrupt-names = "send-empty", "send-not-empty",
				  "recv-empty", "recv-not-empty";
		#mbox-cells = <0>;
		status = "disabled";
	};

	aop_dart: iommu@510f00000 {
		compatible = "apple,t6041-dart", "apple,t8110-dart";
		reg = <0x5 0x10f00000 0x0 0xc000>;
		#iommu-cells = <1>;
		interrupt-parent = <&aic>;
		interrupts = <AIC_IRQ 734 IRQ_TYPE_LEVEL_HIGH>;
		status = "disabled";
	};

	/* The audio fabric's ADMACs: admac-leap-ns (DART stream 10) and admac-base-ns (stream 8) */
	admac0: dma-controller@513300000 {
		compatible = "apple,t6041-admac", "apple,t8132-admac";
		reg = <0x5 0x13300000 0x0 0x34000>;
		#dma-cells = <1>;
		dma-channels = <18>;
		/* the ADT gives the first of the four outputs */
		interrupts-extended = <&aic AIC_IRQ 757 IRQ_TYPE_LEVEL_HIGH>,
				      <0>, <0>, <0>;
		iommus = <&aop_dart 10>;
		status = "disabled";
	};

	admac1: dma-controller@513800000 {
		compatible = "apple,t6041-admac", "apple,t8132-admac";
		reg = <0x5 0x13800000 0x0 0x34000>;
		#dma-cells = <1>;
		dma-channels = <13>;
		/* the ADT gives the first of the four outputs */
		interrupts-extended = <&aic AIC_IRQ 754 IRQ_TYPE_LEVEL_HIGH>,
				      <0>, <0>, <0>;
		iommus = <&aop_dart 8>;
		status = "disabled";
	};

	mtp: mtp@514600000 {
		compatible = "apple,t6041-mtp", "apple,t6041-rtk-helper-asc4",
			     "apple,mtp", "apple,rtk-helper-asc4";
		reg = <0x5 0x14600000 0x0 0x4000>;
		reg-names = "asc";
		mboxes = <&mtp_mbox>;
		iommus = <&mtp_dart 0>;
		#helper-cells = <0>;
		status = "disabled";
	};

	mtp_mbox: mailbox@514608000 {
		compatible = "apple,t6041-asc-mailbox", "apple,asc-mailbox-v4";
		reg = <0x5 0x14608000 0x0 0x4000>;
		interrupt-parent = <&aic>;
		interrupts = <AIC_IRQ 792 IRQ_TYPE_LEVEL_HIGH>,
			     <AIC_IRQ 793 IRQ_TYPE_LEVEL_HIGH>,
			     <AIC_IRQ 794 IRQ_TYPE_LEVEL_HIGH>,
			     <AIC_IRQ 795 IRQ_TYPE_LEVEL_HIGH>;
		interrupt-names = "send-empty", "send-not-empty",
				  "recv-empty", "recv-not-empty";
		#mbox-cells = <0>;
		status = "disabled";
	};

	mtp_dart: iommu@514800000 {
		compatible = "apple,t6041-dart", "apple,t8110-dart";
		reg = <0x5 0x14800000 0x0 0xc000>;
		interrupt-parent = <&aic>;
		interrupts = <AIC_IRQ 775 IRQ_TYPE_LEVEL_HIGH>;
		#iommu-cells = <1>;
		/* ADT "remap": streams 1 2 3 are stream 0 */
		apple,remap-streams = <1 0>, <2 0>, <3 0>;
		status = "disabled";
	};

	mtp_dockchannel: fifo@514b14000 {
		compatible = "apple,t6041-dockchannel", "apple,dockchannel";
		reg = <0x5 0x14b14000 0x0 0x1000>;
		reg-names = "irq";
		interrupt-parent = <&aic>;
		interrupts = <AIC_IRQ 776 IRQ_TYPE_LEVEL_HIGH>;

		ranges = <0x0 0x5 0x14b28000 0x10000>;
		nonposted-mmio;
		#address-cells = <1>;
		#size-cells = <1>;

		interrupt-controller;
		#interrupt-cells = <2>;
		status = "disabled";

		mtp_hid: input@0 {
			compatible = "apple,t6041-dockchannel-hid", "apple,dockchannel-hid";
			reg = <0x0000 0x1000>,
			      <0x4000 0x1000>,
			      <0x8000 0x1000>,
			      <0xc000 0x1000>;
			reg-names = "rmt-config", "rmt-data", "config", "data";
			iommus = <&mtp_dart 0>;
			interrupt-parent = <&mtp_dockchannel>;
			interrupts = <2 IRQ_TYPE_LEVEL_HIGH>,
				     <3 IRQ_TYPE_LEVEL_HIGH>;
			interrupt-names = "tx", "rx";
			apple,fifo-size = <0x800>;
			apple,helper-cpu = <&mtp>;
		};
	};

	pinctrl: pinctrl@51c000000 {
		compatible = "apple,t6041-pinctrl", "apple,t8103-pinctrl";
		reg = <0x5 0x1c000000 0x0 0x4000>;

		gpio-controller;
		#gpio-cells = <2>;
		gpio-ranges = <&pinctrl 0 0 200>;
		apple,npins = <200>;

		interrupt-controller;
		#interrupt-cells = <2>;
		interrupt-parent = <&aic>;
		interrupts = <AIC_IRQ 478 IRQ_TYPE_LEVEL_HIGH>,
			     <AIC_IRQ 479 IRQ_TYPE_LEVEL_HIGH>,
			     <AIC_IRQ 480 IRQ_TYPE_LEVEL_HIGH>,
			     <AIC_IRQ 481 IRQ_TYPE_LEVEL_HIGH>,
			     <AIC_IRQ 482 IRQ_TYPE_LEVEL_HIGH>,
			     <AIC_IRQ 483 IRQ_TYPE_LEVEL_HIGH>,
			     <AIC_IRQ 484 IRQ_TYPE_LEVEL_HIGH>;
		status = "disabled";

		/* I2C is function 1 (ADT gpio-iic_scl/sda) */
		i2c1_pins: i2c1-pins {
			pinmux = <APPLE_PINMUX(58, 1)>,
				 <APPLE_PINMUX(59, 1)>;
		};

		i2c2_pins: i2c2-pins {
			pinmux = <APPLE_PINMUX(60, 1)>,
				 <APPLE_PINMUX(61, 1)>;
		};

		i2c3_pins: i2c3-pins {
			pinmux = <APPLE_PINMUX(62, 1)>,
				 <APPLE_PINMUX(63, 1)>;
		};

		i2c4_pins: i2c4-pins {
			pinmux = <APPLE_PINMUX(64, 1)>,
				 <APPLE_PINMUX(65, 1)>;
		};

		i2c6_pins: i2c6-pins {
			pinmux = <APPLE_PINMUX(68, 1)>,
				 <APPLE_PINMUX(69, 1)>;
		};

		i2c8_pins: i2c8-pins {
			pinmux = <APPLE_PINMUX(72, 1)>,
				 <APPLE_PINMUX(73, 1)>;
		};
	};

	/*
	 * ISP (ADT isp0, firmware loaded by iBoot). "coproc" is the
	 * coprocessor up to its control block; "mbox", "gpio" and "mbox2" are
	 * the interrupt words, the firmware handshake words and the doorbell
	 * of its mailbox at +0x2924000. The first of the ADT's four
	 * interrupts carries the mailbox.
	 */
	isp: isp@580000000 {
		compatible = "apple,t6041-isp", "apple,isp";
		reg = <0x5 0x80000000 0x0 0x1604000>,
		      <0x5 0x82924000 0x0 0x40>,
		      <0x5 0x829241d0 0x0 0x20>,
		      <0x5 0x82924464 0x0 0x10>;
		reg-names = "coproc", "mbox", "gpio", "mbox2";
		interrupt-parent = <&aic>;
		interrupts = <AIC_IRQ 646 IRQ_TYPE_LEVEL_HIGH>;
		iommus = <&isp_dart0 0>, <&isp_dart1 0>, <&isp_dart2 0>;
		power-domains = <&ps_isp_sys>, <&ps_isp_cpu>, <&ps_isp_fe>,
				<&ps_isp_dprx>, <&ps_isp_secure>, <&ps_isp_be>,
				<&ps_isp_clr>, <&ps_ispsens0>;
		/* the shared memory window above the firmware's 32 MiB */
		apple,dart-vm-size = /bits/ 64 <0xde600000>;
		status = "disabled";
	};

	/*
	 * ADT dart-isp0: three instances on one interrupt; ADT "remap": streams
	 * 1, 6, 7, 10 and 11 are stream 0.
	 */
	isp_dart0: iommu@5828c0000 {
		compatible = "apple,t6041-dart", "apple,t8110-dart";
		reg = <0x5 0x828c0000 0x0 0xc000>;
		#iommu-cells = <1>;
		interrupt-parent = <&aic>;
		interrupts = <AIC_IRQ 664 IRQ_TYPE_LEVEL_HIGH>;
		power-domains = <&ps_isp_sys>;
		apple,remap-streams = <1 0>, <6 0>, <7 0>, <10 0>, <11 0>;
		status = "disabled";
	};

	isp_dart1: iommu@5828e0000 {
		compatible = "apple,t6041-dart", "apple,t8110-dart";
		reg = <0x5 0x828e0000 0x0 0xc000>;
		#iommu-cells = <1>;
		interrupt-parent = <&aic>;
		interrupts = <AIC_IRQ 664 IRQ_TYPE_LEVEL_HIGH>;
		power-domains = <&ps_isp_sys>;
		apple,remap-streams = <1 0>, <6 0>, <7 0>, <10 0>, <11 0>;
		status = "disabled";
	};

	isp_dart2: iommu@582900000 {
		compatible = "apple,t6041-dart", "apple,t8110-dart";
		reg = <0x5 0x82900000 0x0 0xc000>;
		#iommu-cells = <1>;
		interrupt-parent = <&aic>;
		interrupts = <AIC_IRQ 664 IRQ_TYPE_LEVEL_HIGH>;
		power-domains = <&ps_isp_sys>;
		apple,remap-streams = <1 0>, <6 0>, <7 0>, <10 0>, <11 0>;
		status = "disabled";
	};

	/*
	 * The three Type-C ports (ADT usb-drdN, atc-phyN, dart-usbN,
	 * acio-phy-cpuN) and the SPMI buses of their PD controllers.
	 */
	nub_spmi_a0: spmi@509188000 {
		compatible = "apple,t6041-spmi", "apple,t8103-spmi";
		reg = <0x5 0x09188000 0x0 0x100>;
		#address-cells = <2>;
		#size-cells = <0>;
		#interrupt-cells = <2>;
		interrupt-controller;
		interrupt-parent = <&aic>;
		interrupts = <AIC_IRQ 866 IRQ_TYPE_LEVEL_HIGH>;
		power-domains = <&ps_nub_spmi_a0>;
		status = "disabled";
	};

	nub_spmi_a1: spmi@509198000 {
		compatible = "apple,t6041-spmi", "apple,t8103-spmi";
		reg = <0x5 0x09198000 0x0 0x100>;
		#address-cells = <2>;
		#size-cells = <0>;
		#interrupt-cells = <2>;
		interrupt-controller;
		interrupt-parent = <&aic>;
		interrupts = <AIC_IRQ 868 IRQ_TYPE_LEVEL_HIGH>;
		power-domains = <&ps_nub_spmi_a1>;
		status = "disabled";
	};

	atcphy0: phy@382a90000 {
		compatible = "apple,t6040-atcphy";
		reg = <0x3 0x82a90000 0x0 0x4000>,
		      <0x3 0x82800000 0x0 0x4000>,
		      <0x3 0x82a84000 0x0 0x4000>,
		      <0x3 0x83000000 0x0 0x30000>,
		      <0x3 0x83200000 0x0 0x4000>,
		      <0x3 0x83140000 0x0 0x4000>,
		      <0x3 0x830c0000 0x0 0x10000>,
		      <0x3 0x80000000 0x0 0x8000>,
		      <0x3 0x80020000 0x0 0x4000>,
		      <0x3 0x83244000 0x0 0x4000>,
		      <0x3 0x83250000 0x0 0x4000>;
		reg-names = "bank0", "bank1", "pipehandler", "core", "cfg", "cpu",
			    "cpu-data", "axi2af", "axi2af-lioa", "fabric", "common-cfg";
		#phy-cells = <1>;
		#reset-cells = <0>;
		power-domains = <&ps_atc0_common_dp>;
		mboxes = <&atcphy0_mbox>;
		mbox-names = "phy-cpu";
		nonposted-mmio;
		orientation-switch;
		status = "disabled";
	};

	atcphy0_mbox: mailbox@383148000 {
		compatible = "apple,t6041-asc-mailbox", "apple,asc-mailbox-v4";
		reg = <0x3 0x83148000 0x0 0x4000>;
		interrupt-parent = <&aic>;
		interrupts = <AIC_IRQ 938 IRQ_TYPE_LEVEL_HIGH>,
			     <AIC_IRQ 939 IRQ_TYPE_LEVEL_HIGH>,
			     <AIC_IRQ 940 IRQ_TYPE_LEVEL_HIGH>,
			     <AIC_IRQ 941 IRQ_TYPE_LEVEL_HIGH>;
		interrupt-names = "send-empty", "send-not-empty",
				  "recv-empty", "recv-not-empty";
		#mbox-cells = <0>;
		power-domains = <&ps_atc0_phymxwrap>;
		status = "disabled";
	};

	dwc3_0_dart_0: iommu@382f00000 {
		compatible = "apple,t6041-dart", "apple,t8110-dart";
		reg = <0x3 0x82f00000 0x0 0xc000>;
		interrupt-parent = <&aic>;
		interrupts = <AIC_IRQ 1623 IRQ_TYPE_LEVEL_HIGH>;
		power-domains = <&ps_atc0_usb>;
		#iommu-cells = <1>;
		status = "disabled";
	};

	dwc3_0_dart_1: iommu@382f80000 {
		compatible = "apple,t6041-dart", "apple,t8110-dart";
		reg = <0x3 0x82f80000 0x0 0xc000>;
		interrupt-parent = <&aic>;
		interrupts = <AIC_IRQ 1623 IRQ_TYPE_LEVEL_HIGH>;
		power-domains = <&ps_atc0_usb>;
		#iommu-cells = <1>;
		status = "disabled";
	};

	dwc3_0: usb@382280000 {
		compatible = "apple,t6040-dwc3", "apple,t8103-dwc3";
		reg = <0x3 0x82280000 0x0 0xcd00>,
		      <0x3 0x8228cd00 0x0 0x3200>,
		      <0x3 0x82200000 0x0 0x4000>;
		reg-names = "dwc3-core", "dwc3-apple", "drd-cfg";
		interrupt-parent = <&aic>;
		interrupts = <AIC_IRQ 1619 IRQ_TYPE_LEVEL_HIGH>;
		/*
		 * A role switch rather than a fixed host: the PD controller
		 * resets the eUSB2 repeater on every connect, so the PHY and
		 * the core start after the attach and stop on detach.
		 */
		dr_mode = "otg";
		usb-role-switch;
		role-switch-default-mode = "host";
		iommus = <&dwc3_0_dart_0 0>, <&dwc3_0_dart_1 1>;
		power-domains = <&ps_atc0_usb>;
		resets = <&atcphy0>;
		phys = <&atcphy0 PHY_TYPE_USB2>, <&atcphy0 PHY_TYPE_USB3>;
		phy-names = "usb2-phy", "usb3-phy";
		status = "disabled";
	};

	atcphy1: phy@38aa90000 {
		compatible = "apple,t6040-atcphy";
		reg = <0x3 0x8aa90000 0x0 0x4000>,
		      <0x3 0x8a800000 0x0 0x4000>,
		      <0x3 0x8aa84000 0x0 0x4000>,
		      <0x3 0x8b000000 0x0 0x30000>,
		      <0x3 0x8b200000 0x0 0x4000>,
		      <0x3 0x8b140000 0x0 0x4000>,
		      <0x3 0x8b0c0000 0x0 0x10000>,
		      <0x3 0x88000000 0x0 0x8000>,
		      <0x3 0x88020000 0x0 0x4000>,
		      <0x3 0x8b244000 0x0 0x4000>,
		      <0x3 0x8b250000 0x0 0x4000>;
		reg-names = "bank0", "bank1", "pipehandler", "core", "cfg", "cpu",
			    "cpu-data", "axi2af", "axi2af-lioa", "fabric", "common-cfg";
		#phy-cells = <1>;
		#reset-cells = <0>;
		power-domains = <&ps_atc1_common_dp>;
		mboxes = <&atcphy1_mbox>;
		mbox-names = "phy-cpu";
		nonposted-mmio;
		orientation-switch;
		status = "disabled";
	};

	atcphy1_mbox: mailbox@38b148000 {
		compatible = "apple,t6041-asc-mailbox", "apple,asc-mailbox-v4";
		reg = <0x3 0x8b148000 0x0 0x4000>;
		interrupt-parent = <&aic>;
		interrupts = <AIC_IRQ 948 IRQ_TYPE_LEVEL_HIGH>,
			     <AIC_IRQ 949 IRQ_TYPE_LEVEL_HIGH>,
			     <AIC_IRQ 950 IRQ_TYPE_LEVEL_HIGH>,
			     <AIC_IRQ 951 IRQ_TYPE_LEVEL_HIGH>;
		interrupt-names = "send-empty", "send-not-empty",
				  "recv-empty", "recv-not-empty";
		#mbox-cells = <0>;
		power-domains = <&ps_atc1_phymxwrap>;
		status = "disabled";
	};

	dwc3_1_dart_0: iommu@38af00000 {
		compatible = "apple,t6041-dart", "apple,t8110-dart";
		reg = <0x3 0x8af00000 0x0 0xc000>;
		interrupt-parent = <&aic>;
		interrupts = <AIC_IRQ 1655 IRQ_TYPE_LEVEL_HIGH>;
		power-domains = <&ps_atc1_usb>;
		#iommu-cells = <1>;
		status = "disabled";
	};

	dwc3_1_dart_1: iommu@38af80000 {
		compatible = "apple,t6041-dart", "apple,t8110-dart";
		reg = <0x3 0x8af80000 0x0 0xc000>;
		interrupt-parent = <&aic>;
		interrupts = <AIC_IRQ 1655 IRQ_TYPE_LEVEL_HIGH>;
		power-domains = <&ps_atc1_usb>;
		#iommu-cells = <1>;
		status = "disabled";
	};

	dwc3_1: usb@38a280000 {
		compatible = "apple,t6040-dwc3", "apple,t8103-dwc3";
		reg = <0x3 0x8a280000 0x0 0xcd00>,
		      <0x3 0x8a28cd00 0x0 0x3200>,
		      <0x3 0x8a200000 0x0 0x4000>;
		reg-names = "dwc3-core", "dwc3-apple", "drd-cfg";
		interrupt-parent = <&aic>;
		interrupts = <AIC_IRQ 1651 IRQ_TYPE_LEVEL_HIGH>;
		/*
		 * A role switch rather than a fixed host: the PD controller
		 * resets the eUSB2 repeater on every connect, so the PHY and
		 * the core start after the attach and stop on detach.
		 */
		dr_mode = "otg";
		usb-role-switch;
		role-switch-default-mode = "host";
		iommus = <&dwc3_1_dart_0 0>, <&dwc3_1_dart_1 1>;
		power-domains = <&ps_atc1_usb>;
		resets = <&atcphy1>;
		phys = <&atcphy1 PHY_TYPE_USB2>, <&atcphy1 PHY_TYPE_USB3>;
		phy-names = "usb2-phy", "usb3-phy";
		status = "disabled";
	};

	atcphy2: phy@392a90000 {
		compatible = "apple,t6040-atcphy";
		reg = <0x3 0x92a90000 0x0 0x4000>,
		      <0x3 0x92800000 0x0 0x4000>,
		      <0x3 0x92a84000 0x0 0x4000>,
		      <0x3 0x93000000 0x0 0x30000>,
		      <0x3 0x93200000 0x0 0x4000>,
		      <0x3 0x93140000 0x0 0x4000>,
		      <0x3 0x930c0000 0x0 0x10000>,
		      <0x3 0x90000000 0x0 0x8000>,
		      <0x3 0x90020000 0x0 0x4000>,
		      <0x3 0x93244000 0x0 0x4000>,
		      <0x3 0x93250000 0x0 0x4000>;
		reg-names = "bank0", "bank1", "pipehandler", "core", "cfg", "cpu",
			    "cpu-data", "axi2af", "axi2af-lioa", "fabric", "common-cfg";
		#phy-cells = <1>;
		#reset-cells = <0>;
		power-domains = <&ps_atc2_common_dp>;
		mboxes = <&atcphy2_mbox>;
		mbox-names = "phy-cpu";
		nonposted-mmio;
		orientation-switch;
		status = "disabled";
	};

	atcphy2_mbox: mailbox@393148000 {
		compatible = "apple,t6041-asc-mailbox", "apple,asc-mailbox-v4";
		reg = <0x3 0x93148000 0x0 0x4000>;
		interrupt-parent = <&aic>;
		interrupts = <AIC_IRQ 958 IRQ_TYPE_LEVEL_HIGH>,
			     <AIC_IRQ 959 IRQ_TYPE_LEVEL_HIGH>,
			     <AIC_IRQ 960 IRQ_TYPE_LEVEL_HIGH>,
			     <AIC_IRQ 961 IRQ_TYPE_LEVEL_HIGH>;
		interrupt-names = "send-empty", "send-not-empty",
				  "recv-empty", "recv-not-empty";
		#mbox-cells = <0>;
		power-domains = <&ps_atc2_phymxwrap>;
		status = "disabled";
	};

	dwc3_2_dart_0: iommu@392f00000 {
		compatible = "apple,t6041-dart", "apple,t8110-dart";
		reg = <0x3 0x92f00000 0x0 0xc000>;
		interrupt-parent = <&aic>;
		interrupts = <AIC_IRQ 1687 IRQ_TYPE_LEVEL_HIGH>;
		power-domains = <&ps_atc2_usb>;
		#iommu-cells = <1>;
		status = "disabled";
	};

	dwc3_2_dart_1: iommu@392f80000 {
		compatible = "apple,t6041-dart", "apple,t8110-dart";
		reg = <0x3 0x92f80000 0x0 0xc000>;
		interrupt-parent = <&aic>;
		interrupts = <AIC_IRQ 1687 IRQ_TYPE_LEVEL_HIGH>;
		power-domains = <&ps_atc2_usb>;
		#iommu-cells = <1>;
		status = "disabled";
	};

	dwc3_2: usb@392280000 {
		compatible = "apple,t6040-dwc3", "apple,t8103-dwc3";
		reg = <0x3 0x92280000 0x0 0xcd00>,
		      <0x3 0x9228cd00 0x0 0x3200>,
		      <0x3 0x92200000 0x0 0x4000>;
		reg-names = "dwc3-core", "dwc3-apple", "drd-cfg";
		interrupt-parent = <&aic>;
		interrupts = <AIC_IRQ 1683 IRQ_TYPE_LEVEL_HIGH>;
		/*
		 * A role switch rather than a fixed host: the PD controller
		 * resets the eUSB2 repeater on every connect, so the PHY and
		 * the core start after the attach and stop on detach.
		 */
		dr_mode = "otg";
		usb-role-switch;
		role-switch-default-mode = "host";
		iommus = <&dwc3_2_dart_0 0>, <&dwc3_2_dart_1 1>;
		power-domains = <&ps_atc2_usb>;
		resets = <&atcphy2>;
		phys = <&atcphy2 PHY_TYPE_USB2>, <&atcphy2 PHY_TYPE_USB3>;
		phy-names = "usb2-phy", "usb3-phy";
		status = "disabled";
	};

	dispext0_dart: iommu@3a2300000 {
		compatible = "apple,t6041-dart", "apple,t8110-dart";
		reg = <0x3 0xa2300000 0x0 0xc000>;
		#iommu-cells = <1>;
		apple,dma-range = <0x100 0x0 0x10 0x0>;
		interrupt-parent = <&aic>;
		interrupts = <AIC_IRQ 1165 IRQ_TYPE_LEVEL_HIGH>;
		status = "disabled";
	};

	dcpext0_dart: iommu@3a2340000 {
		compatible = "apple,t6041-dart", "apple,t8110-dart";
		reg = <0x3 0xa2340000 0x0 0x20000>;
		#iommu-cells = <1>;
		apple,dma-range = <0x100 0x0 0x10 0x0>;
		interrupt-parent = <&aic>;
		interrupts = <AIC_IRQ 1165 IRQ_TYPE_LEVEL_HIGH>;
		status = "disabled";
	};

	ane0_dart0: iommu@485800000 {
		compatible = "apple,t6041-dart", "apple,t8110-dart";
		reg = <0x4 0x85800000 0x0 0xc000>;
		#iommu-cells = <1>;
		interrupt-parent = <&aic>;
		interrupts = <AIC_IRQ 1055 IRQ_TYPE_LEVEL_HIGH>;
		power-domains = <&ps_ane_sys>;
		/* Include firmware identity MMIO pages below the preload DVAs. */
		apple,dma-range = <0x0 0x0 0x400 0x0>;
		status = "disabled";
	};

	ane0_dart1: iommu@485820000 {
		compatible = "apple,t6041-dart", "apple,t8110-dart";
		reg = <0x4 0x85820000 0x0 0xc000>;
		#iommu-cells = <1>;
		interrupt-parent = <&aic>;
		interrupts = <AIC_IRQ 1055 IRQ_TYPE_LEVEL_HIGH>;
		power-domains = <&ps_ane_sys>;
		/* Include firmware identity MMIO pages below the preload DVAs. */
		apple,dma-range = <0x0 0x0 0x400 0x0>;
		status = "disabled";
	};

	ane0_dart2: iommu@485840000 {
		compatible = "apple,t6041-dart", "apple,t8110-dart";
		reg = <0x4 0x85840000 0x0 0xc000>;
		#iommu-cells = <1>;
		interrupt-parent = <&aic>;
		interrupts = <AIC_IRQ 1055 IRQ_TYPE_LEVEL_HIGH>;
		power-domains = <&ps_ane_sys>;
		/* Include firmware identity MMIO pages below the preload DVAs. */
		apple,dma-range = <0x0 0x0 0x400 0x0>;
		status = "disabled";
	};

	dispext1_dart: iommu@602300000 {
		compatible = "apple,t6041-dart", "apple,t8110-dart";
		reg = <0x6 0x02300000 0x0 0xc000>;
		#iommu-cells = <1>;
		apple,dma-range = <0x100 0x0 0x10 0x0>;
		interrupt-parent = <&aic>;
		interrupts = <AIC_IRQ 1237 IRQ_TYPE_LEVEL_HIGH>;
		status = "disabled";
	};

	dcpext1_dart: iommu@602340000 {
		compatible = "apple,t6041-dart", "apple,t8110-dart";
		reg = <0x6 0x02340000 0x0 0xc000>;
		#iommu-cells = <1>;
		apple,dma-range = <0x100 0x0 0x10 0x0>;
		interrupt-parent = <&aic>;
		interrupts = <AIC_IRQ 1237 IRQ_TYPE_LEVEL_HIGH>;
		status = "disabled";
	};

	pinctrl_aop: pinctrl@510824000 {
		compatible = "apple,t6041-pinctrl", "apple,t8103-pinctrl";
		reg = <0x5 0x10824000 0x0 0x4000>;
		clocks = <&clkref>;
		gpio-controller;
		#gpio-cells = <2>;
		gpio-ranges = <&pinctrl_aop 0 0 85>;
		apple,npins = <85>;
		interrupt-controller;
		#interrupt-cells = <2>;
		interrupt-parent = <&aic>;
		interrupts = <AIC_IRQ 700 IRQ_TYPE_LEVEL_HIGH>,
			     <AIC_IRQ 701 IRQ_TYPE_LEVEL_HIGH>,
			     <AIC_IRQ 702 IRQ_TYPE_LEVEL_HIGH>,
			     <AIC_IRQ 703 IRQ_TYPE_LEVEL_HIGH>,
			     <AIC_IRQ 704 IRQ_TYPE_LEVEL_HIGH>,
			     <AIC_IRQ 705 IRQ_TYPE_LEVEL_HIGH>,
			     <AIC_IRQ 706 IRQ_TYPE_LEVEL_HIGH>;
		/* Coprocessor pins and interrupt groups need an ownership handoff. */
		status = "disabled";
	};

	/*
	 * Disabled until the H16 firmware path is proven on hardware. The
	 * loader fills the preload reservations and the firmware IOVAs from
	 * the ADT, so enabling it then only takes status = "okay" here and on
	 * the three DARTs.
	 */
	ane: ane@484000000 {
		compatible = "apple,t6041-ane";
		reg = <0x4 0x84000000 0x0 0x2000000>,
		      <0x5 0x02280000 0x0 0x18000>,
		      <0x5 0x022a0000 0x0 0x4000>,
		      <0x5 0x003c0000 0x0 0x30000>,
		      <0x2 0x12000000 0x0 0xff4000>,
		      <0x5 0x22000000 0x0 0x2000000>,
		      <0x5 0x08374000 0x0 0x4000>;
		reg-names = "engine", "pmgr", "aux-0", "aux-1", "aux-2",
			    "aux-3", "aux-4";
		interrupt-parent = <&aic>;
		interrupts = <AIC_IRQ 1054 IRQ_TYPE_LEVEL_HIGH>;
		/* Stream 0 only: the MPM stream 11 is not given to the host. */
		iommus = <&ane0_dart0 0>, <&ane0_dart1 0>, <&ane0_dart2 0>;
		power-domains = <&ps_ane_sys>, <&ps_ane_cpu>, <&ps_ane_mpm>,
				<&ps_ane_td>, <&ps_ane_base>;
		apple,ane-type = <0x110>;
		apple,firmware-preloaded;
		/* Inclusive DAPF bounds, in hardware record order. */
		apple,dapf-ranges = /bits/ 64 <0x5022803c0 0x5022803c3>,
				    /bits/ 64 <0x50228c000 0x50228c01b>,
				    /bits/ 64 <0x581668000 0x581668003>,
				    /bits/ 64 <0x28a668000 0x28a668003>;
		/* Default firmware layout; the loader rewrites it from the ADT. */
		apple,firmware-iovas = /bits/ 64 <0x10000000000 0x100000c0000>;
		/* The bootloader supplies the physical TEXT/DATA reservations. */
		status = "disabled";
	};

	serial0: serial@429200000 {
		compatible = "apple,s5l-uart";
		reg = <0x4 0x29200000 0x0 0x4000>;
		reg-io-width = <4>;
		interrupt-parent = <&aic>;
		interrupts = <AIC_IRQ 1559 IRQ_TYPE_LEVEL_HIGH>;
		clocks = <&clkref>, <&clkref>;
		clock-names = "uart", "clk_uart_baud0";
	};

	cpu_pmu: pmu {
		compatible = "apple,t6040-pmu";
		interrupt-parent = <&aic>;
		/* The AIC raises both clusters' PMU FIQs as this one. */
		interrupts = <AIC_FIQ AIC_CPU_PMU_P IRQ_TYPE_LEVEL_HIGH>;
	};

	pmgr_venc: power-management@502808000 {
		compatible = "apple,t6041-pmgr", "apple,t8103-pmgr", "syscon", "simple-mfd";
		reg = <0x5 0x02808000 0x0 0x4000>;
		#address-cells = <1>;
		#size-cells = <1>;
	};

	/* Additional DARTs; enabled together with their DMA consumers. */
	ave0_dart1: iommu@283080000 {
		compatible = "apple,t6041-dart", "apple,t8110-dart";
		reg = <0x2 0x83080000 0x0 0xc000>;
		#iommu-cells = <1>;
		apple,dma-range = <0x100 0x00004000 0x0 0xffffc000>;
		interrupt-parent = <&aic>;
		interrupts = <AIC_IRQ 1461 IRQ_TYPE_LEVEL_HIGH>;
		power-domains = <&ps_venc0_sys>;
		status = "disabled";
	};

	ave0_dart0: iommu@2830a0000 {
		compatible = "apple,t6041-dart", "apple,t8110-dart";
		reg = <0x2 0x830a0000 0x0 0xc000>;
		#iommu-cells = <1>;
		apple,dma-range = <0x100 0x00004000 0x0 0xffffc000>;
		interrupt-parent = <&aic>;
		interrupts = <AIC_IRQ 1461 IRQ_TYPE_LEVEL_HIGH>;
		power-domains = <&ps_venc0_sys>;
		status = "disabled";
	};

	sio_dart: iommu@429060000 {
		compatible = "apple,t6041-dart", "apple,t8110-dart";
		reg = <0x4 0x29060000 0x0 0x20000>;
		#iommu-cells = <1>;
		apple,dma-range = <0x100 0x1c000 0x2ff 0xfffe4000>;
		interrupt-parent = <&aic>;
		interrupts = <AIC_IRQ 1587 IRQ_TYPE_LEVEL_HIGH>;
		power-domains = <&ps_sio>;
		status = "disabled";
	};

	jpeg0: jpeg@487000000 {
		compatible = "apple,t6041-jpeg";
		reg = <0x4 0x87000000 0x0 0x4000>;
		interrupt-parent = <&aic>;
		interrupts = <AIC_IRQ 1538 IRQ_TYPE_LEVEL_HIGH>;
		iommus = <&jpeg0_dart 0>;
		power-domains = <&ps_jpg>;
		apple,dma-range = /bits/ 64 <0x10000000000 0x100000000>;
		status = "disabled";
	};

	jpeg0_dart: iommu@487020000 {
		compatible = "apple,t6041-dart", "apple,t8110-dart";
		reg = <0x4 0x87020000 0x0 0xc000>;
		#iommu-cells = <1>;
		apple,dma-range = <0x100 0x0 0x300 0x0>;
		interrupt-parent = <&aic>;
		interrupts = <AIC_IRQ 1539 IRQ_TYPE_LEVEL_HIGH>;
		power-domains = <&ps_jpg>;
		status = "disabled";
	};

	jpeg1: jpeg@487060000 {
		compatible = "apple,t6041-jpeg";
		reg = <0x4 0x87060000 0x0 0x4000>;
		interrupt-parent = <&aic>;
		interrupts = <AIC_IRQ 1543 IRQ_TYPE_LEVEL_HIGH>;
		iommus = <&jpeg1_dart 0>;
		power-domains = <&ps_jpg>;
		apple,dma-range = /bits/ 64 <0x10000000000 0x100000000>;
		status = "disabled";
	};

	jpeg1_dart: iommu@487080000 {
		compatible = "apple,t6041-dart", "apple,t8110-dart";
		reg = <0x4 0x87080000 0x0 0xc000>;
		#iommu-cells = <1>;
		apple,dma-range = <0x100 0x0 0x300 0x0>;
		interrupt-parent = <&aic>;
		interrupts = <AIC_IRQ 1544 IRQ_TYPE_LEVEL_HIGH>;
		power-domains = <&ps_jpg>;
		status = "disabled";
	};

	/* The QSPIMC input is ADT clock 434 (200 MHz). */
	clk_200m: clock-200m {
		compatible = "fixed-clock";
		#clock-cells = <0>;
		clock-frequency = <200000000>;
		clock-output-names = "clk_200m";
	};

	qspi: spi@429118000 {
		compatible = "apple,t6041-qspi";
		reg = <0x4 0x29118000 0x0 0x4800>;
		interrupt-parent = <&aic>;
		interrupts = <AIC_IRQ 1573 IRQ_TYPE_LEVEL_HIGH>;
		clocks = <&clk_200m>;
		power-domains = <&ps_qspi>;
		#address-cells = <1>;
		#size-cells = <0>;
		/* Boards enable it with their flash and its nvram partition. */
		status = "disabled";
	};

	/* The loader supplies the SIO firmware regions and protocol tables. */
	sio: dma-controller@429e00000 {
		compatible = "apple,t6041-sio";
		reg = <0x4 0x29e00000 0x0 0x8000>;
		dma-channels = <128>;
		#dma-cells = <1>;
		mboxes = <&sio_mbox>;
		iommus = <&sio_dart 0>;
		power-domains = <&ps_sio_cpu>;
		status = "disabled";
	};

	sio_mbox: mailbox@429e08000 {
		compatible = "apple,t6041-asc-mailbox", "apple,asc-mailbox-v4";
		reg = <0x4 0x29e08000 0x0 0x4000>;
		interrupt-parent = <&aic>;
		interrupts = <AIC_IRQ 1591 IRQ_TYPE_LEVEL_HIGH>,
			     <AIC_IRQ 1592 IRQ_TYPE_LEVEL_HIGH>,
			     <AIC_IRQ 1593 IRQ_TYPE_LEVEL_HIGH>,
			     <AIC_IRQ 1594 IRQ_TYPE_LEVEL_HIGH>;
		interrupt-names = "send-empty", "send-not-empty",
				  "recv-empty", "recv-not-empty";
		#mbox-cells = <0>;
		power-domains = <&ps_sio_cpu>;
		status = "disabled";
	};

	/* The video encoder stays disabled until its firmware backend is available. */
	ave: video-codec@283100000 {
		compatible = "apple,t6041-ave";
		reg = <0x2 0x83100000 0x0 0x45c000>,
		      <0x2 0x83050000 0x0 0x4000>,
		      <0x2 0x83800000 0x0 0x800000>;
		reg-names = "codec", "mailbox", "coproc";
		interrupt-parent = <&aic>;
		interrupts = <AIC_IRQ 1464 IRQ_TYPE_LEVEL_HIGH>,
			     <AIC_IRQ 1458 IRQ_TYPE_LEVEL_HIGH>,
			     <AIC_IRQ 1457 IRQ_TYPE_LEVEL_HIGH>,
			     <AIC_IRQ 1460 IRQ_TYPE_LEVEL_HIGH>,
			     <AIC_IRQ 1459 IRQ_TYPE_LEVEL_HIGH>;
		power-domains = <&ps_venc0_dma>, <&ps_venc0_pipe4>,
				<&ps_venc0_pipe5>, <&ps_venc0_me0>, <&ps_venc0_me1>;
		power-domain-names = "dma", "pipe4", "pipe5", "me0", "me1";
		iommus = <&ave0_dart0 0>, <&ave0_dart1 0>;
		status = "disabled";
	};
};

#include "t604x-pmgr.dtsi"
